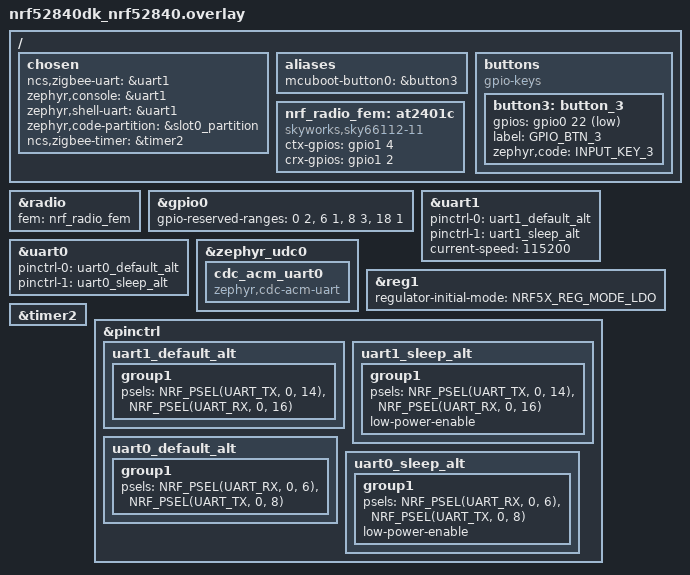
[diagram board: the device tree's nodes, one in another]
/*
 * Copyright (c) 2021-2022 Nordic Semiconductor ASA
 *
 * SPDX-License-Identifier: LicenseRef-Nordic-5-Clause
 */

/ {
	chosen {
		ncs,zigbee-uart = &uart1;
        zephyr,console = &uart1;
		zephyr,shell-uart = &uart1;
		zephyr,code-partition = &slot0_partition;
		ncs,zigbee-timer = &timer2;
	};

    aliases {
		mcuboot-button0 = &button3;

		/delete-property/ pwm-led0;
		/delete-property/ led0;
		/delete-property/ led1;
		/delete-property/ led2;
		/delete-property/ led3;
		/delete-property/ sw0;
		/delete-property/ sw1;
		/delete-property/ sw2;
		/delete-property/ bootloader-led0;
		/delete-property/ mcuboot-led0;
	};

	buttons {
		compatible = "gpio-keys";
		button3: button_3 {
			gpios = <&gpio0 22 (GPIO_PULL_UP | GPIO_ACTIVE_LOW)>;
			label = "GPIO_BTN_3";
			zephyr,code = <INPUT_KEY_3>;
			status = "okay";
		};
	};

	nrf_radio_fem: at2401c {
		compatible = "skyworks,sky66112-11", "generic-fem-two-ctrl-pins";
		ctx-gpios = <&gpio1 4 GPIO_ACTIVE_HIGH>;
		crx-gpios = <&gpio1 2 GPIO_ACTIVE_HIGH>;
	};

	/delete-node/ pwmleds;
	/delete-node/ connector;
	/delete-node/ analog-connector;
};

/delete-node/ &spi3;
/delete-node/ &qspi;
/delete-node/ &qspi_default;
/delete-node/ &qspi_sleep;
/delete-node/ &led0;
/delete-node/ &led1;
/delete-node/ &led2;
/delete-node/ &led3;
/delete-node/ &button0;
/delete-node/ &button1;
/delete-node/ &button2;

&radio {
	fem = <&nrf_radio_fem>;
};

&gpio0 {
	gpio-reserved-ranges = <0 2>, <6 1>, <8 3>, <18 1>;
};

&uart1 {
	pinctrl-0 = <&uart1_default_alt>;
	pinctrl-1 = <&uart1_sleep_alt>;
	pinctrl-names = "default", "sleep";
	current-speed = <115200>;
	status = "okay";
};

&uart0 {
	pinctrl-0 = <&uart0_default_alt>;
	pinctrl-1 = <&uart0_sleep_alt>;
	pinctrl-names = "default", "sleep";
};

&zephyr_udc0 {
	cdc_acm_uart0: cdc_acm_uart0 {
		compatible = "zephyr,cdc-acm-uart";
	};
};

&reg1 {
	regulator-initial-mode = <NRF5X_REG_MODE_LDO>;
};

&timer2 {
	status = "okay";
};

&pinctrl {
	uart1_default_alt: uart1_default_alt {
		group1 {
			psels = <NRF_PSEL(UART_TX, 0, 14)>, <NRF_PSEL(UART_RX, 0, 16)>;
		};
	};

	uart1_sleep_alt: uart1_sleep_alt {
		group1 {
			psels = <NRF_PSEL(UART_TX, 0, 14)>, <NRF_PSEL(UART_RX, 0, 16)>;
			low-power-enable;
		};
	};

	uart0_default_alt: uart0_default_alt {
		group1 {
			psels = <NRF_PSEL(UART_RX, 0, 6)>, <NRF_PSEL(UART_TX, 0, 8)>;
		};
	};

	uart0_sleep_alt: uart0_sleep_alt {
		group1 {
			psels = <NRF_PSEL(UART_RX, 0, 6)>, <NRF_PSEL(UART_TX, 0, 8)>;
			low-power-enable;
		};
	};
};
